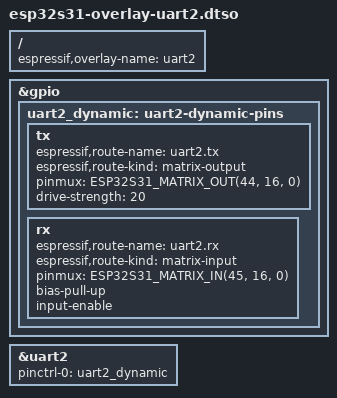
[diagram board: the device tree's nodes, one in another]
// SPDX-License-Identifier: GPL-2.0+
/dts-v1/;
/plugin/;

#include <dt-bindings/pinctrl/esp32s31-pinmux.h>

/ {
	espressif,overlay-name = "uart2";
};

&gpio {
	uart2_dynamic: uart2-dynamic-pins {
		tx {
			espressif,route-name = "uart2.tx";
			espressif,route-kind = "matrix-output";
			pinmux = <ESP32S31_MATRIX_OUT(44, 16, 0)>;
			drive-strength = <20>;
		};
		rx {
			espressif,route-name = "uart2.rx";
			espressif,route-kind = "matrix-input";
			pinmux = <ESP32S31_MATRIX_IN(45, 16, 0)>;
			bias-pull-up;
			input-enable;
		};
	};
};

&uart2 {
	pinctrl-names = "default";
	pinctrl-0 = <&uart2_dynamic>;
	status = "okay";
};
